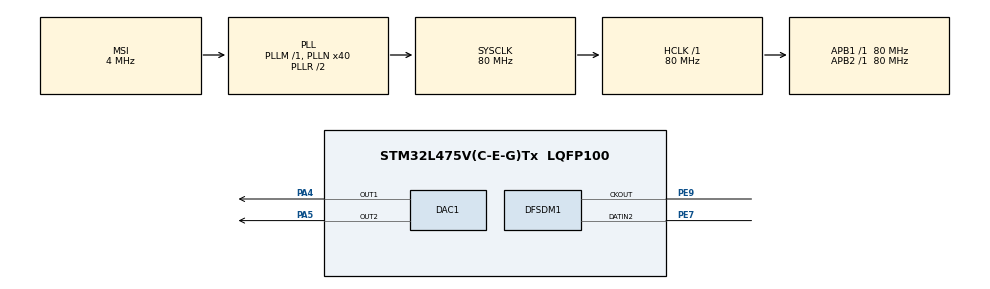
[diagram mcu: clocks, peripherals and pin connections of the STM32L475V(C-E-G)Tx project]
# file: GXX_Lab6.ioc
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DAC1.DAC_Channel-DAC_OUT2=DAC_CHANNEL_2
DAC1.DAC_Trigger-DAC_OUT2=DAC_TRIGGER_NONE
DFSDM1.Divider=20
DFSDM1.DmaMode_reg_FIL0=ENABLE
DFSDM1.DmaMode_reg_FIL1=ENABLE
DFSDM1.FastMode_reg_FIL0=ENABLE
DFSDM1.FastMode_reg_FIL1=ENABLE
DFSDM1.Filter_regChannel_FIL0=DFSDM_CHANNEL_1
DFSDM1.Filter_regChannel_FIL1=DFSDM_CHANNEL_2
DFSDM1.Fosr_FIL0=125
DFSDM1.Fosr_FIL1=125
DFSDM1.Offset_CH1=-4095
DFSDM1.Offset_CH2=-4095
DFSDM1.RightBitShift_CH1=20
DFSDM1.RightBitShift_CH2=0x8
DFSDM1.Selection=DFSDM_CHANNEL_OUTPUT_CLOCK_AUDIO
DFSDM1.SincOrder_FIL0=DFSDM_FILTER_SINC4_ORDER
DFSDM1.SincOrder_FIL1=DFSDM_FILTER_SINC4_ORDER
DFSDM1.Type_spi_CH1=DFSDM_CHANNEL_SPI_FALLING
Dma.DAC_CH1.2.Direction=DMA_MEMORY_TO_PERIPH
Dma.DAC_CH1.2.Instance=DMA2_Channel4
Dma.DAC_CH1.2.MemDataAlignment=DMA_MDATAALIGN_HALFWORD
Dma.DAC_CH1.2.MemInc=DMA_MINC_ENABLE
Dma.DAC_CH1.2.Mode=DMA_CIRCULAR
Dma.DAC_CH1.2.PeriphDataAlignment=DMA_PDATAALIGN_HALFWORD
Dma.DAC_CH1.2.PeriphInc=DMA_PINC_DISABLE
Dma.DAC_CH1.2.Priority=DMA_PRIORITY_LOW
Dma.DAC_CH2.3.Direction=DMA_MEMORY_TO_PERIPH
Dma.DAC_CH2.3.Instance=DMA2_Channel5
Dma.DAC_CH2.3.MemDataAlignment=DMA_MDATAALIGN_HALFWORD
Dma.DAC_CH2.3.MemInc=DMA_MINC_ENABLE
Dma.DAC_CH2.3.Mode=DMA_CIRCULAR
Dma.DAC_CH2.3.PeriphDataAlignment=DMA_PDATAALIGN_HALFWORD
Dma.DAC_CH2.3.PeriphInc=DMA_PINC_DISABLE
Dma.DAC_CH2.3.Priority=DMA_PRIORITY_LOW
Dma.DFSDM1_FLT0.0.Direction=DMA_PERIPH_TO_MEMORY
Dma.DFSDM1_FLT0.0.Instance=DMA1_Channel4
Dma.DFSDM1_FLT0.0.MemDataAlignment=DMA_MDATAALIGN_WORD
Dma.DFSDM1_FLT0.0.MemInc=DMA_MINC_ENABLE
Dma.DFSDM1_FLT0.0.Mode=DMA_CIRCULAR
Dma.DFSDM1_FLT0.0.PeriphDataAlignment=DMA_PDATAALIGN_WORD
Dma.DFSDM1_FLT0.0.PeriphInc=DMA_PINC_DISABLE
Dma.DFSDM1_FLT0.0.Priority=DMA_PRIORITY_LOW
Dma.DFSDM1_FLT1.1.Direction=DMA_PERIPH_TO_MEMORY
Dma.DFSDM1_FLT1.1.Instance=DMA1_Channel5
Dma.DFSDM1_FLT1.1.MemDataAlignment=DMA_MDATAALIGN_WORD
Dma.DFSDM1_FLT1.1.MemInc=DMA_MINC_ENABLE
Dma.DFSDM1_FLT1.1.Mode=DMA_CIRCULAR
Dma.DFSDM1_FLT1.1.PeriphDataAlignment=DMA_PDATAALIGN_WORD
Dma.DFSDM1_FLT1.1.PeriphInc=DMA_PINC_DISABLE
Dma.DFSDM1_FLT1.1.Priority=DMA_PRIORITY_LOW
Dma.Request0=DFSDM1_FLT0
Dma.Request1=DFSDM1_FLT1
Dma.Request2=DAC_CH1
Dma.Request3=DAC_CH2
Mcu.Family=STM32L4
Mcu.Name=STM32L475V(C-E-G)Tx
Mcu.Package=LQFP100
NVIC.DMA1_Channel4_IRQn=true\:0\:0\:false\:false\:true\:false
NVIC.DMA1_Channel5_IRQn=true\:0\:0\:false\:false\:true\:false
NVIC.DMA2_Channel4_IRQn=true\:0\:0\:false\:false\:true\:false
NVIC.DMA2_Channel5_IRQn=true\:0\:0\:false\:false\:true\:false
NVIC.PriorityGroup=NVIC_PRIORITYGROUP_4
NVIC.TIM6_DAC_IRQn=true\:0\:0\:false\:false\:true\:true
PA4.Signal=COMP_DAC11_group
PA5.Signal=COMP_DAC12_group
PE7.Signal=S_DATAIN2DFSDM1
PE9.Signal=S_CKOUTDFSDM1
ProjectManager.HeapSize=0x200
ProjectManager.StackSize=0x400
ProjectManager.TargetToolchain=MDK-ARM V5
RCC.ADCFreq_Value=140000000
RCC.AHBFreq_Value=80000000
RCC.APB1Freq_Value=80000000
RCC.APB1TimFreq_Value=80000000
RCC.APB2Freq_Value=80000000
RCC.APB2TimFreq_Value=80000000
RCC.CortexFreq_Value=80000000
RCC.HCLKFreq_Value=80000000
RCC.HSE_VALUE=8000000
RCC.HSI_VALUE=16000000
RCC.LSE_VALUE=32768
RCC.MSI_VALUE=4000000
RCC.PLLN=40
RCC.PLLSAI1N=70
RCC.SYSCLKFreq_VALUE=80000000
RCC.SYSCLKSource=RCC_SYSCLKSOURCE_PLLCLK
RCC.USBFreq_Value=140000000
RCC.VCOOutputFreq_Value=160000000
SH.COMP_DAC11_group.0=DAC1_OUT1,DAC_OUT1
SH.COMP_DAC12_group.0=DAC1_OUT2,DAC_OUT2
SH.S_CKOUTDFSDM1.0=DFSDM1_CKOUT,PDM_SPI_input_from_ch2_and_internal_clock
SH.S_CKOUTDFSDM1.1=DFSDM1_CKOUT,PDM_SPI_Input_from_ch12_and_Internal_Clock
SH.S_DATAIN2DFSDM1.0=DFSDM1_DATIN2,PDM_SPI_input_from_ch2_and_internal_clock
SH.S_DATAIN2DFSDM1.1=DFSDM1_DATIN2,PDM_SPI_Input_from_ch12_and_Internal_Clock
TIM6.Period=50
TIM6.Prescaler=100
VP_TIM6_VS_ClockSourceINT.Mode=Enable_Timer
board=custom

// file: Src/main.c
/**
  ******************************************************************************
  * @file           : main.c
  * @brief          : Main program body
  ******************************************************************************
  ** This notice applies to any and all portions of this file
  * that are not between comment pairs USER CODE BEGIN and
  * USER CODE END. Other portions of this file, whether
  * inserted by the user or by software development tools
  * are owned by their respective copyright owners.
  *
  * COPYRIGHT(c) 2019 STMicroelectronics
  *
  * Redistribution and use in source and binary forms, with or without modification,
  * are permitted provided that the following conditions are met:
  *   1. Redistributions of source code must retain the above copyright notice,
  *      this list of conditions and the following disclaimer.
  *   2. Redistributions in binary form must reproduce the above copyright notice,
  *      this list of conditions and the following disclaimer in the documentation
  *      and/or other materials provided with the distribution.
  *   3. Neither the name of STMicroelectronics nor the names of its contributors
  *      may be used to endorse or promote products derived from this software
  *      without specific prior written permission.
  *
  * THIS SOFTWARE IS PROVIDED BY THE COPYRIGHT HOLDERS AND CONTRIBUTORS "AS IS"
  * AND ANY EXPRESS OR IMPLIED WARRANTIES, INCLUDING, BUT NOT LIMITED TO, THE
  * IMPLIED WARRANTIES OF MERCHANTABILITY AND FITNESS FOR A PARTICULAR PURPOSE ARE
  * DISCLAIMED. IN NO EVENT SHALL THE COPYRIGHT HOLDER OR CONTRIBUTORS BE LIABLE
  * FOR ANY DIRECT, INDIRECT, INCIDENTAL, SPECIAL, EXEMPLARY, OR CONSEQUENTIAL
  * DAMAGES (INCLUDING, BUT NOT LIMITED TO, PROCUREMENT OF SUBSTITUTE GOODS OR
  * SERVICES; LOSS OF USE, DATA, OR PROFITS; OR BUSINESS INTERRUPTION) HOWEVER
  * CAUSED AND ON ANY THEORY OF LIABILITY, WHETHER IN CONTRACT, STRICT LIABILITY,
  * OR TORT (INCLUDING NEGLIGENCE OR OTHERWISE) ARISING IN ANY WAY OUT OF THE USE
  * OF THIS SOFTWARE, EVEN IF ADVISED OF THE POSSIBILITY OF SUCH DAMAGE.
  *
  ******************************************************************************
  */
#include "main.h"
#include "stm32l4xx_hal.h"

DAC_HandleTypeDef hdac1;
DMA_HandleTypeDef hdma_dac_ch1;
DMA_HandleTypeDef hdma_dac_ch2;

DFSDM_Filter_HandleTypeDef hdfsdm1_filter0;
DFSDM_Filter_HandleTypeDef hdfsdm1_filter1;
DFSDM_Channel_HandleTypeDef hdfsdm1_channel1;
DFSDM_Channel_HandleTypeDef hdfsdm1_channel2;
DMA_HandleTypeDef hdma_dfsdm1_flt0;
DMA_HandleTypeDef hdma_dfsdm1_flt1;

TIM_HandleTypeDef htim6;

/* USER CODE BEGIN PV */
/* Private variables ---------------------------------------------------------*/
#define BufferSize  8000
int audioBufferLeft[BufferSize];	//audio buffer for left output
int audioBufferRight[BufferSize];	//audio buffer for right output
/* USER CODE END PV */

void SystemClock_Config(void);
static void MX_GPIO_Init(void);
static void MX_DMA_Init(void);
static void MX_DFSDM1_Init(void);
static void MX_DAC1_Init(void);
static void MX_TIM6_Init(void);

/* USER CODE BEGIN PFP */
/* Private function prototypes -----------------------------------------------*/

/* USER CODE END PFP */

int main(void)
{

  /* MCU Configuration----------------------------------------------------------*/

  /* Reset of all peripherals, Initializes the Flash interface and the Systick. */
  HAL_Init();

  /* Configure the system clock */
  SystemClock_Config();

  /* Initialize all configured peripherals */
  MX_GPIO_Init();
  MX_DMA_Init();
  MX_DFSDM1_Init();
  MX_DAC1_Init();
  MX_TIM6_Init();
  /* USER CODE BEGIN 2 */

	//Starting DFSDM DMA mode
  HAL_DFSDM_FilterRegularStart_DMA(&hdfsdm1_filter0, audioBufferRight, BufferSize);
  HAL_DFSDM_FilterRegularStart_DMA(&hdfsdm1_filter1, audioBufferLeft, BufferSize);

	//Starting DAC Channel 1 and DAC Channel 2 DMA mode
  HAL_DAC_Start_DMA (&hdac1, DAC_CHANNEL_1, (uint32_t *) audioBufferLeft, BufferSize, DAC_ALIGN_12B_R);
	HAL_DAC_Start_DMA (&hdac1, DAC_CHANNEL_2, (uint32_t *) audioBufferRight, BufferSize, DAC_ALIGN_12B_R);

	HAL_Delay(500);	//500 ms delay

	//Timer6 start to trigger DAC output
	HAL_TIM_Base_Start(&htim6);
  /* USER CODE END 2 */

  /* Infinite loop */
  while (1)
  {

  }

}

void SystemClock_Config(void)
{

  RCC_OscInitTypeDef RCC_OscInitStruct;
  RCC_ClkInitTypeDef RCC_ClkInitStruct;
  RCC_PeriphCLKInitTypeDef PeriphClkInit;

    /**Initializes the CPU, AHB and APB busses clocks
    */
  RCC_OscInitStruct.OscillatorType = RCC_OSCILLATORTYPE_MSI;
  RCC_OscInitStruct.MSIState = RCC_MSI_ON;
  RCC_OscInitStruct.MSICalibrationValue = 0;
  RCC_OscInitStruct.MSIClockRange = RCC_MSIRANGE_6;
  RCC_OscInitStruct.PLL.PLLState = RCC_PLL_ON;
  RCC_OscInitStruct.PLL.PLLSource = RCC_PLLSOURCE_MSI;
  RCC_OscInitStruct.PLL.PLLM = 1;
  RCC_OscInitStruct.PLL.PLLN = 40;
  RCC_OscInitStruct.PLL.PLLP = RCC_PLLP_DIV7;
  RCC_OscInitStruct.PLL.PLLQ = RCC_PLLQ_DIV2;
  RCC_OscInitStruct.PLL.PLLR = RCC_PLLR_DIV2;
  if (HAL_RCC_OscConfig(&RCC_OscInitStruct) != HAL_OK)
  {
    _Error_Handler(__FILE__, __LINE__);
  }

    /**Initializes the CPU, AHB and APB busses clocks
    */
  RCC_ClkInitStruct.ClockType = RCC_CLOCKTYPE_HCLK|RCC_CLOCKTYPE_SYSCLK
                              |RCC_CLOCKTYPE_PCLK1|RCC_CLOCKTYPE_PCLK2;
  RCC_ClkInitStruct.SYSCLKSource = RCC_SYSCLKSOURCE_PLLCLK;
  RCC_ClkInitStruct.AHBCLKDivider = RCC_SYSCLK_DIV1;
  RCC_ClkInitStruct.APB1CLKDivider = RCC_HCLK_DIV1;
  RCC_ClkInitStruct.APB2CLKDivider = RCC_HCLK_DIV1;

  if (HAL_RCC_ClockConfig(&RCC_ClkInitStruct, FLASH_LATENCY_4) != HAL_OK)
  {
    _Error_Handler(__FILE__, __LINE__);
  }

  PeriphClkInit.PeriphClockSelection = RCC_PERIPHCLK_SAI1|RCC_PERIPHCLK_DFSDM1;
  PeriphClkInit.Sai1ClockSelection = RCC_SAI1CLKSOURCE_PLLSAI1;
  PeriphClkInit.Dfsdm1ClockSelection = RCC_DFSDM1CLKSOURCE_PCLK;
  PeriphClkInit.PLLSAI1.PLLSAI1Source = RCC_PLLSOURCE_MSI;
  PeriphClkInit.PLLSAI1.PLLSAI1M = 1;
  PeriphClkInit.PLLSAI1.PLLSAI1N = 70;
  PeriphClkInit.PLLSAI1.PLLSAI1P = RCC_PLLP_DIV7;
  PeriphClkInit.PLLSAI1.PLLSAI1Q = RCC_PLLQ_DIV2;
  PeriphClkInit.PLLSAI1.PLLSAI1R = RCC_PLLR_DIV2;
  PeriphClkInit.PLLSAI1.PLLSAI1ClockOut = RCC_PLLSAI1_SAI1CLK;
  if (HAL_RCCEx_PeriphCLKConfig(&PeriphClkInit) != HAL_OK)
  {
    _Error_Handler(__FILE__, __LINE__);
  }

    /**Configure the main internal regulator output voltage
    */
  if (HAL_PWREx_ControlVoltageScaling(PWR_REGULATOR_VOLTAGE_SCALE1) != HAL_OK)
  {
    _Error_Handler(__FILE__, __LINE__);
  }

    /**Configure the Systick interrupt time
    */
  HAL_SYSTICK_Config(HAL_RCC_GetHCLKFreq()/1000);

    /**Configure the Systick
    */
  HAL_SYSTICK_CLKSourceConfig(SYSTICK_CLKSOURCE_HCLK);

  /* SysTick_IRQn interrupt configuration */
  HAL_NVIC_SetPriority(SysTick_IRQn, 0, 0);
}

/* DAC1 init function */
static void MX_DAC1_Init(void)
{

  DAC_ChannelConfTypeDef sConfig;

    /**DAC Initialization
    */
  hdac1.Instance = DAC1;
  if (HAL_DAC_Init(&hdac1) != HAL_OK)
  {
    _Error_Handler(__FILE__, __LINE__);
  }

    /**DAC channel OUT1 config
    */
  sConfig.DAC_SampleAndHold = DAC_SAMPLEANDHOLD_DISABLE;
  sConfig.DAC_Trigger = DAC_TRIGGER_T6_TRGO;
  sConfig.DAC_OutputBuffer = DAC_OUTPUTBUFFER_ENABLE;
  sConfig.DAC_ConnectOnChipPeripheral = DAC_CHIPCONNECT_DISABLE;
  sConfig.DAC_UserTrimming = DAC_TRIMMING_FACTORY;
  if (HAL_DAC_ConfigChannel(&hdac1, &sConfig, DAC_CHANNEL_1) != HAL_OK)
  {
    _Error_Handler(__FILE__, __LINE__);
  }

    /**DAC channel OUT2 config
    */
  sConfig.DAC_ConnectOnChipPeripheral = DAC_CHIPCONNECT_DISABLE;
  if (HAL_DAC_ConfigChannel(&hdac1, &sConfig, DAC_CHANNEL_2) != HAL_OK)
  {
    _Error_Handler(__FILE__, __LINE__);
  }

}

/* DFSDM1 init function */
static void MX_DFSDM1_Init(void)
{

  hdfsdm1_filter0.Instance = DFSDM1_Filter0;
  hdfsdm1_filter0.Init.RegularParam.Trigger = DFSDM_FILTER_SW_TRIGGER;
  hdfsdm1_filter0.Init.RegularParam.FastMode = ENABLE;
  hdfsdm1_filter0.Init.RegularParam.DmaMode = ENABLE;
  hdfsdm1_filter0.Init.FilterParam.SincOrder = DFSDM_FILTER_SINC4_ORDER;
  hdfsdm1_filter0.Init.FilterParam.Oversampling = 128;	//Oversampling ~= Microphone Clock Frequency/Output Frequency
  hdfsdm1_filter0.Init.FilterParam.IntOversampling = 1;
  if (HAL_DFSDM_FilterInit(&hdfsdm1_filter0) != HAL_OK)
  {
    _Error_Handler(__FILE__, __LINE__);
  }

  hdfsdm1_filter1.Instance = DFSDM1_Filter1;
  hdfsdm1_filter1.Init.RegularParam.Trigger = DFSDM_FILTER_SW_TRIGGER;
  hdfsdm1_filter1.Init.RegularParam.FastMode = ENABLE;	//
  hdfsdm1_filter1.Init.RegularParam.DmaMode = ENABLE;
  hdfsdm1_filter1.Init.FilterParam.SincOrder = DFSDM_FILTER_SINC4_ORDER;
  hdfsdm1_filter1.Init.FilterParam.Oversampling = 128;	//Oversampling ~= Microphone Clock Frequency/Output Frequency
  hdfsdm1_filter1.Init.FilterParam.IntOversampling = 1;
  if (HAL_DFSDM_FilterInit(&hdfsdm1_filter1) != HAL_OK)
  {
    _Error_Handler(__FILE__, __LINE__);
  }

  hdfsdm1_channel1.Instance = DFSDM1_Channel1;
  hdfsdm1_channel1.Init.OutputClock.Activation = ENABLE;
  hdfsdm1_channel1.Init.OutputClock.Selection = DFSDM_CHANNEL_OUTPUT_CLOCK_AUDIO;	//40 MHz
  hdfsdm1_channel1.Init.OutputClock.Divider = 20;	//Microphone clock = OutputClock/Divider = 2 MHz
  hdfsdm1_channel1.Init.Input.Multiplexer = DFSDM_CHANNEL_EXTERNAL_INPUTS;
  hdfsdm1_channel1.Init.Input.DataPacking = DFSDM_CHANNEL_STANDARD_MODE;
  hdfsdm1_channel1.Init.Input.Pins = DFSDM_CHANNEL_FOLLOWING_CHANNEL_PINS;
  hdfsdm1_channel1.Init.SerialInterface.Type = DFSDM_CHANNEL_SPI_FALLING;
  hdfsdm1_channel1.Init.SerialInterface.SpiClock = DFSDM_CHANNEL_SPI_CLOCK_INTERNAL;
  hdfsdm1_channel1.Init.Awd.FilterOrder = DFSDM_CHANNEL_FASTSINC_ORDER;
  hdfsdm1_channel1.Init.Awd.Oversampling = 1;
  hdfsdm1_channel1.Init.Offset = 0;
  hdfsdm1_channel1.Init.RightBitShift = 22;
  if (HAL_DFSDM_ChannelInit(&hdfsdm1_channel1) != HAL_OK)
  {
    _Error_Handler(__FILE__, __LINE__);
  }

  hdfsdm1_channel2.Instance = DFSDM1_Channel2;
  hdfsdm1_channel2.Init.OutputClock.Activation = ENABLE;
  hdfsdm1_channel2.Init.OutputClock.Selection = DFSDM_CHANNEL_OUTPUT_CLOCK_AUDIO;	//40 MHz
  hdfsdm1_channel2.Init.OutputClock.Divider = 20;	//Microphone clock = OutputClock/Divider
  hdfsdm1_channel2.Init.Input.Multiplexer = DFSDM_CHANNEL_EXTERNAL_INPUTS;
  hdfsdm1_channel2.Init.Input.DataPacking = DFSDM_CHANNEL_STANDARD_MODE;
  hdfsdm1_channel2.Init.Input.Pins = DFSDM_CHANNEL_SAME_CHANNEL_PINS;
  hdfsdm1_channel2.Init.SerialInterface.Type = DFSDM_CHANNEL_SPI_RISING;
  hdfsdm1_channel2.Init.SerialInterface.SpiClock = DFSDM_CHANNEL_SPI_CLOCK_INTERNAL;
  hdfsdm1_channel2.Init.Awd.FilterOrder = DFSDM_CHANNEL_FASTSINC_ORDER;
  hdfsdm1_channel2.Init.Awd.Oversampling = 1;
  hdfsdm1_channel2.Init.Offset = 0;
  hdfsdm1_channel2.Init.RightBitShift = 22;
  if (HAL_DFSDM_ChannelInit(&hdfsdm1_channel2) != HAL_OK)
  {
    _Error_Handler(__FILE__, __LINE__);
  }

  if (HAL_DFSDM_FilterConfigRegChannel(&hdfsdm1_filter0, DFSDM_CHANNEL_1, DFSDM_CONTINUOUS_CONV_ON) != HAL_OK)
  {
    _Error_Handler(__FILE__, __LINE__);
  }

  if (HAL_DFSDM_FilterConfigRegChannel(&hdfsdm1_filter1, DFSDM_CHANNEL_2, DFSDM_CONTINUOUS_CONV_ON) != HAL_OK)
  {
    _Error_Handler(__FILE__, __LINE__);
  }

}

/* TIM6 init function */
static void MX_TIM6_Init(void)
{

  TIM_MasterConfigTypeDef sMasterConfig;

  htim6.Instance = TIM6;
  htim6.Init.Prescaler = 100;
  htim6.Init.CounterMode = TIM_COUNTERMODE_UP;
  htim6.Init.Period = 50;
  htim6.Init.AutoReloadPreload = TIM_AUTORELOAD_PRELOAD_DISABLE;
  if (HAL_TIM_Base_Init(&htim6) != HAL_OK)
  {
    _Error_Handler(__FILE__, __LINE__);
  }

  sMasterConfig.MasterOutputTrigger = TIM_TRGO_UPDATE;
  sMasterConfig.MasterSlaveMode = TIM_MASTERSLAVEMODE_DISABLE;
  if (HAL_TIMEx_MasterConfigSynchronization(&htim6, &sMasterConfig) != HAL_OK)
  {
    _Error_Handler(__FILE__, __LINE__);
  }

}

static void MX_DMA_Init(void)
{
  /* DMA controller clock enable */
  __HAL_RCC_DMA1_CLK_ENABLE();
  __HAL_RCC_DMA2_CLK_ENABLE();

  /* DMA interrupt init */
  /* DMA1_Channel4_IRQn interrupt configuration */
  HAL_NVIC_SetPriority(DMA1_Channel4_IRQn, 0, 0);
  HAL_NVIC_EnableIRQ(DMA1_Channel4_IRQn);
  /* DMA1_Channel5_IRQn interrupt configuration */
  HAL_NVIC_SetPriority(DMA1_Channel5_IRQn, 0, 0);
  HAL_NVIC_EnableIRQ(DMA1_Channel5_IRQn);
  /* DMA2_Channel4_IRQn interrupt configuration */
  HAL_NVIC_SetPriority(DMA2_Channel4_IRQn, 0, 0);
  HAL_NVIC_EnableIRQ(DMA2_Channel4_IRQn);
  /* DMA2_Channel5_IRQn interrupt configuration */
  HAL_NVIC_SetPriority(DMA2_Channel5_IRQn, 0, 0);
  HAL_NVIC_EnableIRQ(DMA2_Channel5_IRQn);
}

/** Pinout Configuration
*/
static void MX_GPIO_Init(void)
{

  /* GPIO Ports Clock Enable */
  __HAL_RCC_GPIOA_CLK_ENABLE();
  __HAL_RCC_GPIOE_CLK_ENABLE();

}

void _Error_Handler(char *file, int line)
{
  while(1)
  {
  }
}

/************************ (C) COPYRIGHT STMicroelectronics *****END OF FILE****/
